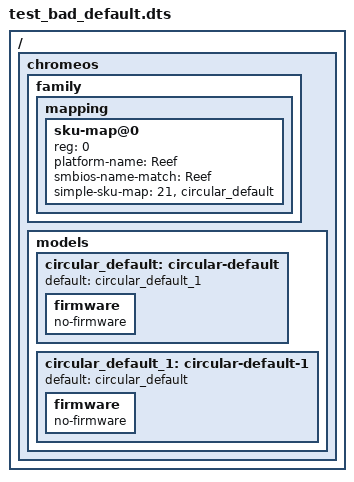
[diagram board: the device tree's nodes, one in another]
/dts-v1/;

/ {
	chromeos {
		family: family {
		};
		models: models {
		};
	};
};

&family {
	mapping {
		#address-cells = <1>;
		#size-cells = <0>;
		sku-map@0 {
			reg = <0>;
			platform-name = "Reef";
			smbios-name-match = "Reef";
			/*
			* This is an example! It does not match any real
			* family.
			*/
			simple-sku-map = <21 &circular_default>;
		};
	};
};

&models {
	circular_default: circular-default {
		default = <&circular_default_1>;
		firmware {
			no-firmware;
		};
	};

	circular_default_1: circular-default-1 {
		default = <&circular_default>;
		firmware {
			no-firmware;
		};
	};
};
